# f28003x_dev_cfg_regs register map
Vendor: Texas Instruments
Peripheral module from a debugger description file (folder C2000).
Address unit: 16 bits
Registers are 32-bit, read-write, no defined reset value unless marked. A register's access mark holds for its fields unless they carry their own. Offsets are as the file gives them; lines under a group give offsets from that group; [hi:lo] are bit positions; {n}, {i} and the like mark numbered series; 'fields as' and 'values as' point back to an identical list; <NAME> marks a mode.

## DEV_CFG_REGS — DEV CFG Registers
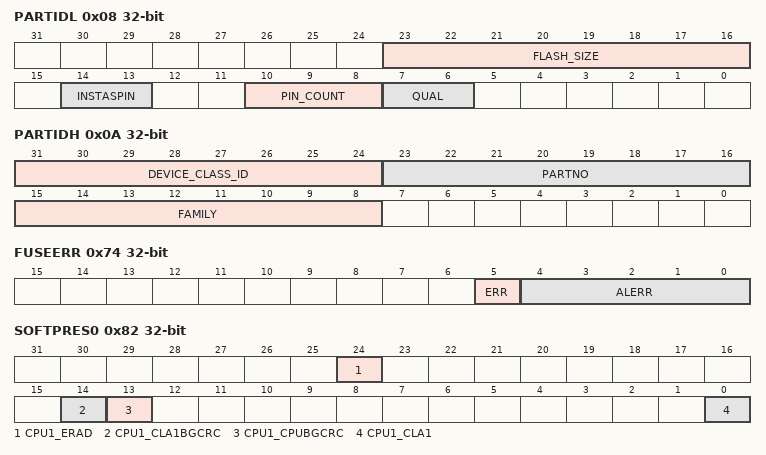
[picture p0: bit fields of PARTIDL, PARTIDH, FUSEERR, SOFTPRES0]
0x08 PARTIDL — Lower 32-bit of Device PART Identification Number
  [23:16] FLASH_SIZE — Flash size in KB
  [14:13] INSTASPIN — Instaspin feature set
  [10:8] PIN_COUNT — Device Pin Count
  [7:6] QUAL — Qualification Status
0x0A PARTIDH access per field — Upper 32-bit of Device PART Identification Number
  [31:24] DEVICE_CLASS_ID ro
  [23:16] PARTNO rw — Device part number
  [15:8] FAMILY rw — Device family
0x0C REVID ro — Device Revision Number
  [15:0] REVID — Device Revision ID. This is specific to the Device
0x74 FUSEERR ro — e-Fuse error Status register
  [5] ERR — Efuse Self Test Error Status
  [4:0] ALERR — Efuse Autoload Error Status
0x82 SOFTPRES0 — Processing Block Software Reset register
  [24] CPU1_ERAD — ERAD Module reset bit
  [14] CPU1_CLA1BGCRC — CLA1BGCRC Module reset bit
  [13] CPU1_CPUBGCRC — CPUBGCRC Module reset bit
  [0] CPU1_CLA1 — CPU1_CLA1 software reset bit
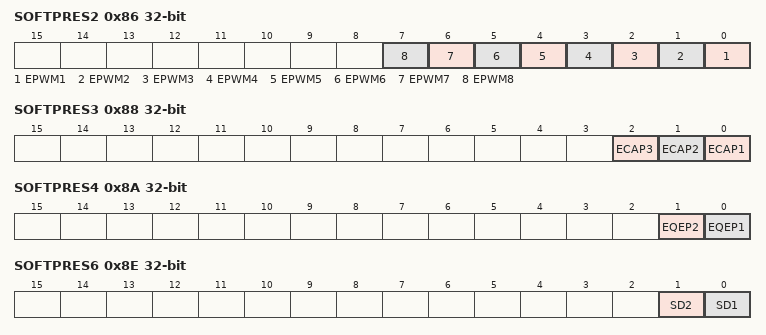
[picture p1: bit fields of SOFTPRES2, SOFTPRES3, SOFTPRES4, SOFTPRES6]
0x86 SOFTPRES2 — EPWM Software Reset register
  [n-1] EPWM{n} (n=1..8) — EPWM{n} software reset bit
0x88 SOFTPRES3 — ECAP Software Reset register
  [2] ECAP3 — ECAP3 software reset bit
  [1] ECAP2 — ECAP2 software reset bit
  [0] ECAP1 — ECAP1 software reset bit
0x8A SOFTPRES4 — EQEP Software Reset register
  [1] EQEP2 — EQEP2 software reset bit
  [0] EQEP1 — EQEP1 software reset bit
0x8E SOFTPRES6 — Sigma Delta Software Reset register
  [1] SD2 — SD2 software reset bit
  [0] SD1 — SD1 software reset bit
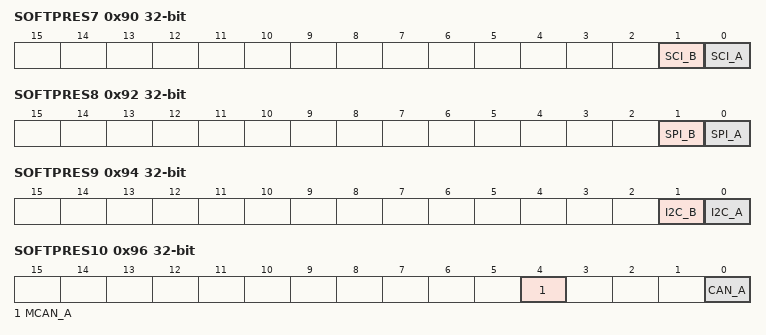
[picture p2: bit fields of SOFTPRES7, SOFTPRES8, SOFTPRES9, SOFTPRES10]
0x90 SOFTPRES7 — SCI Software Reset register
  [1] SCI_B — SCI_B software reset bit
  [0] SCI_A — SCI_A software reset bit
0x92 SOFTPRES8 — SPI Software Reset register
  [1] SPI_B — SPI_B software reset bit
  [0] SPI_A — SPI_A software reset bit
0x94 SOFTPRES9 — I2C Software Reset register
  [1] I2C_B — I2C_B software reset bit
  [0] I2C_A — I2C_A software reset bit
0x96 SOFTPRES10 — CAN Software Reset register
  [4] MCAN_A — MCAN_A software reset bit
  [0] CAN_A — CAN_A software reset bit
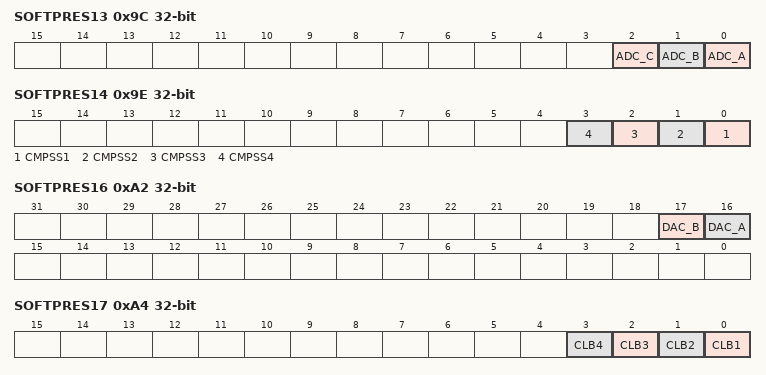
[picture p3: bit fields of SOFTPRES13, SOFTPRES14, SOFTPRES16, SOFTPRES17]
0x9C SOFTPRES13 — ADC Software Reset register
  [2] ADC_C — ADC_C software reset bit
  [1] ADC_B — ADC_B software reset bit
  [0] ADC_A — ADC_A software reset bit
0x9E SOFTPRES14 — CMPSS Software Reset register
  [n-1] CMPSS{n} (n=1..4) — CMPSS{n} software reset bit
0xA2 SOFTPRES16 — DAC Software Reset register
  [17] DAC_B — Buffered_DAC_B software reset bit
  [16] DAC_A — Buffered_DAC_A software reset bit
0xA4 SOFTPRES17 — CLB Software Reset register
  [n-1] CLB{n} (n=1..4) — CLB{n} software reset bit
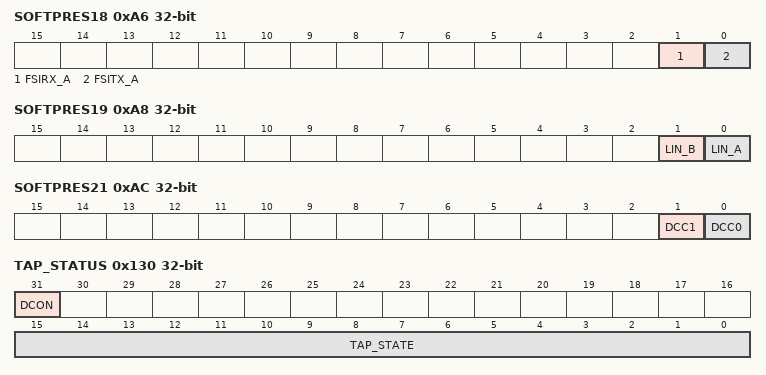
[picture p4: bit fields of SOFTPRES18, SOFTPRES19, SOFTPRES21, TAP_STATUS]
0xA6 SOFTPRES18 — FSI Software Reset register
  [1] FSIRX_A — FSIRX_A software reset bit
  [0] FSITX_A — FSITX_A software reset bit
0xA8 SOFTPRES19 — LIN Software Reset register
  [1] LIN_B — LIN_B software reset bit
  [0] LIN_A — LIN_A software reset bit
0xAA SOFTPRES20 — PMBUS Software Reset register
  [0] PMBUS_A — PMBUS_A software reset bit
0xAC SOFTPRES21 — DCC Software Reset register
  [1] DCC1 — DCC Module reset bit
  [0] DCC0 — DCC Module reset bit
0xB4 SOFTPRES25 — HIC Software Reset register
  [0] HIC_A — HIC Slave and Host controller Reset Bit
0xB6 SOFTPRES26 — AES Software Reset register
  [0] AESA — AES Module Reset Bit
0xB8 SOFTPRES27 — EPG Software Reset register
  [0] EPGA — EPG Module Reset Bit
0x130 TAP_STATUS ro — Status of JTAG State machine and Debugger Connect
  [31] DCON — Debugger Connect Indication
  [15:0] TAP_STATE — Present TAP State
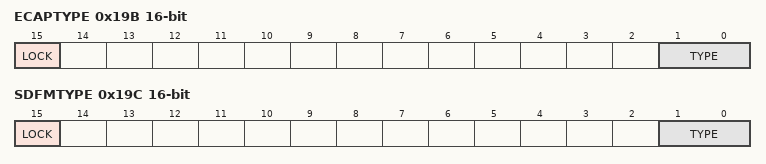
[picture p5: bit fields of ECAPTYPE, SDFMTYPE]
0x19B ECAPTYPE 16-bit — Configures ECAP Type for the device
  [15] LOCK — Lock bit for the register
  [1:0] TYPE — Configure ECAP type
0x19C SDFMTYPE 16-bit — Configures SDFM Type for the device
  [15] LOCK — Lock bit
  [1:0] TYPE — Configure SDFM type
